AUTOSAR XML (schema 4-3-0)
standard types defined: uint8, uint8_DataConstr, boolean, uint16, sint16, sint32
package /ASP_DataTypes
  40 x impl type:
    accPedalPosition: category=VALUE, base-type=BaseTypes/uint8
    accPedalPositionQual: category=VALUE, base-type=BaseTypes/uint8, compu {0=Cx0_Unsafe, 1=Cx1_Safe, 2=Cx2_SNA; unit Enum}
    AEB_Input: category=STRUCTURE
      4 x element, all with category=TYPE_REFERENCE:
        collAvoidSnvtySetting: range raw 0..3, implementation-data-type=collAvoidSnvtySetting
        driverAEBOverrideQual: range raw 0..3, implementation-data-type=driverAEBOverrideQual
        collAvoidSnvtySettingQual: range raw 0..3, implementation-data-type=collAvoidSnvtySettingQual
        driverAEBOverride: implementation-data-type=driverAEBOverride
    brakePedalPressed: category=VALUE, base-type=BaseTypes/boolean, compu {0=Cx0_No, 1=Cx1_Yes; unit Enum}
    brakePedalPressedQual: category=VALUE, base-type=BaseTypes/uint8, compu {0=Cx0_Unsafe, 1=Cx1_Safe, 2=Cx2_SNA; unit Enum}
    brakeTorque: category=VALUE, base-type=BaseTypes/uint16
    collAvoidSnvtySetting: category=VALUE, base-type=BaseTypes/uint8, compu {0=Cx0_NotInUse, 1=Cx1_LoSnvty, 2=Cx2_NormSnvty, 3=Cx3_HiSnvty; unit Enum}
    collAvoidSnvtySettingQual: category=VALUE, base-type=BaseTypes/uint8, compu {0=Cx0_Unsafe, 1=Cx1_Safe, 2=Cx2_SNA; unit Enum}
    Common_Zenuity_Input: category=STRUCTURE
      7 x element, all with category=TYPE_REFERENCE:
        brakePedalPressed: implementation-data-type=brakePedalPressed
        steeringWhlAngle: range raw -16384..16383, implementation-data-type=steeringWhlAngle
        accPedalPositionQual: range raw 0..3, implementation-data-type=accPedalPositionQual
        steeringWhlAngleSpeed: range raw -65536..65535, implementation-data-type=steeringWhlAngleSpeed
        accPedalPosition: range raw 0..100, implementation-data-type=accPedalPosition
        driverBrakeTorque: range raw 0..20000, implementation-data-type=driverBrakeTorque
        brakePedalPressedQual: range raw 0..3, implementation-data-type=brakePedalPressedQual
    driverAEBOverride: category=VALUE, base-type=BaseTypes/boolean, compu {0=Cx0_No, 1=Cx1_Yes; unit Enum}
    driverAEBOverrideQual: category=VALUE, base-type=BaseTypes/uint8, compu {0=Cx0_Unsafe, 1=Cx1_Safe, 2=Cx2_SNA; unit Enum}
    driverBrakeTorque: category=VALUE, base-type=BaseTypes/uint16
    dynamicWheelRadiusFront: category=VALUE, base-type=BaseTypes/uint16
    dynamicWheelRadiusRear: category=VALUE, base-type=BaseTypes/uint16
    EgoMotion: category=STRUCTURE
      20 x element, all with category=TYPE_REFERENCE:
        dynamicWheelRadiusRear: range raw 0..4095, implementation-data-type=dynamicWheelRadiusRear
        lateralAccelerationQual: range raw 0..3, implementation-data-type=lateralAccelerationQual
        lateralAcceleration: range raw -2048..2047, implementation-data-type=lateralAcceleration
        longitudinalSpeedQual: range raw 0..3, implementation-data-type=longitudinalSpeedQual
        wheelSpeedFrontRight: range raw -8192..8191, implementation-data-type=wheelSpeedFrontRight
        dynamicWheelRadiusFront: range raw 0..4095, implementation-data-type=dynamicWheelRadiusFront
        wheelSpeedQual: range raw 0..3, implementation-data-type=wheelSpeedQual
        wheelSpeedFrontLeft: range raw -8192..8191, implementation-data-type=wheelSpeedFrontLeft
        longitudinalSpeed: range raw -8192..8191, implementation-data-type=longitudinalSpeed
        rearWheelAngleQual: range raw 0..3, implementation-data-type=rearWheelAngleQual
        wheelSpeedRearRight: range raw -8192..8191, implementation-data-type=wheelSpeedRearRight
        longitudinalAccelerationQual: range raw 0..3, implementation-data-type=longitudinalAccelerationQual
        frontWheelAngle: range raw -16384..16383, implementation-data-type=frontWheelAngle
        rearWheelAngle: range raw -16384..16383, implementation-data-type=rearWheelAngle
        wheelSpeedRearLeft: range raw -8192..8191, implementation-data-type=wheelSpeedRearLeft
        frontWheelAngleQual: range raw 0..3, implementation-data-type=frontWheelAngleQual
        longitudinalAcceleration: range raw -2048..2047, implementation-data-type=longitudinalAcceleration
        yawRate: implementation-data-type=yawRate
        yawRateQual: range raw 0..3, implementation-data-type=yawRateQual
        brakeTorque: range raw 0..16383, implementation-data-type=brakeTorque
    engineState: category=VALUE, base-type=BaseTypes/uint8, compu {0=Cx0_Stop, 1=Cx1_Start, 2=Cx2_Idle_Unstable (Idle Unstable), 3=Cx3_Idle_Stable (Idle Stable), 4=Cx4_Unlimited, 5=Cx5_Limited, 6=Cx6_SNA; unit Enum}
    frontWheelAngle: category=VALUE, base-type=sint16
    frontWheelAngleQual: category=VALUE, base-type=BaseTypes/uint8, compu {0=Cx0_Unavailable, 1=Cx1_Available, 2=Cx2_SNA; unit Enum}
    ignitionState: category=VALUE, base-type=BaseTypes/uint8, compu {0=Cx0_Lock, 1=Cx1_OFF, 2=Cx2_ACC, 3=Cx3_ON, 4=Cx4_Start, 5=Cx5_SNA; unit Enum}
    lateralAcceleration: category=VALUE, base-type=sint16
    lateralAccelerationQual: category=VALUE, base-type=BaseTypes/uint8, compu {0=Cx0_Unavailable, 1=Cx1_Available, 2=Cx2_SNA; unit Enum}
    longitudinalAcceleration: category=VALUE, base-type=sint16
    longitudinalAccelerationQual: category=VALUE, base-type=BaseTypes/uint8, compu {0=Cx0_Unavailable, 1=Cx1_Available, 2=Cx2_SNA; unit Enum}
    longitudinalSpeed: category=VALUE, base-type=sint16
    longitudinalSpeedQual: category=VALUE, base-type=BaseTypes/uint8, compu {0=Cx0_Unsafe, 1=Cx1_Safe, 2=Cx2_SNA; unit Enum}
    PositionInfoType: category=STRUCTURE, sw-calibration-access=READ-ONLY, type-emitter=RTE
      element countryCode: category=VALUE, base-type=BaseTypes/uint16, sw-calibration-access=READ-ONLY, invalid-value=1023  # Current country in ISO 3166-1 numerical
    rearWheelAngle: category=VALUE, base-type=sint16
    rearWheelAngleQual: category=VALUE, base-type=BaseTypes/uint8, compu {0=Cx0_Unavailable, 1=Cx1_Available, 2=Cx2_SNA; unit Enum}
    steeringWhlAngle: category=VALUE, base-type=sint16
    steeringWhlAngleSpeed: category=VALUE, base-type=sint32
    suspensionType: category=VALUE, base-type=BaseTypes/uint8
    turnIndicator: category=VALUE, base-type=BaseTypes/uint8
    VehicleData: category=STRUCTURE
      4 x element, all with category=TYPE_REFERENCE, range raw 0..7:
        suspensionType: implementation-data-type=suspensionType
        ignitionState: implementation-data-type=ignitionState
        turnIndicator: implementation-data-type=turnIndicator
        engineState: implementation-data-type=engineState
    wheelSpeedFrontLeft: category=VALUE, base-type=sint16
    wheelSpeedFrontRight: category=VALUE, base-type=sint16
    wheelSpeedQual: category=VALUE, base-type=BaseTypes/uint8, compu {0=Cx0_Unavailable, 1=Cx1_Available, 2=Cx2_SNA; unit Enum}
    wheelSpeedRearLeft: category=VALUE, base-type=sint16
    wheelSpeedRearRight: category=VALUE, base-type=sint16
    yawRate: category=VALUE, base-type=sint16
    yawRateQual: category=VALUE, base-type=BaseTypes/uint8, compu {0=Cx0_Unavailable, 1=Cx1_Available, 2=Cx2_SNA; unit Enum}
package /ASP_DataTypes/Units
  unit U_Enum: display-name=Enum, factor-si-to-unit=1, offset-si-to-unit=0
package /ASP_PortInterfaces
  sender receiver interface ASP_AEB_Input: invalidation-policy{data-element=AEB_Input, handle-invalid=DONT-INVALIDATE}
    data AEB_Input: type=AEB_Input
  sender receiver interface ASP_Common_Zenuity_Input: invalidation-policy{data-element=Common_Zenuity_Input, handle-invalid=DONT-INVALIDATE}
    data Common_Zenuity_Input: type=Common_Zenuity_Input
  sender receiver interface ASP_VehicleInput
    data EgoMotionElement: type=EgoMotion
    data PositionInfo: type=PositionInfoType
    data VehicleDataElement: type=VehicleData
    invalidation-policys:
      data-element=EgoMotionElement, handle-invalid=DONT-INVALIDATE
      data-element=VehicleDataElement, handle-invalid=DONT-INVALIDATE
      data-element=PositionInfo, handle-invalid=DONT-INVALIDATE
package /ComponentTypes/HkmcComponent/HkmcVehicleInputAdap
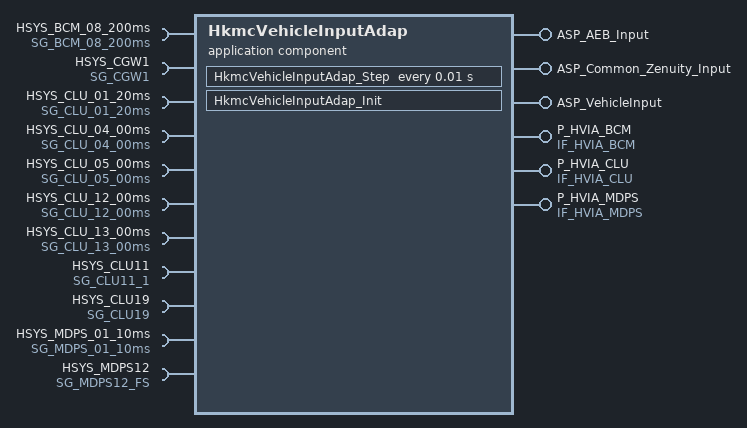
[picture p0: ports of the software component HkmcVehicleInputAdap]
  application sw component type HkmcVehicleInputAdap
    6 x provide port:
      ASP_AEB_Input: nonqueued-sender-com-spec{data-element=AEB_Input, init-value=fields=[collAvoidSnvtySetting:0, driverAEBOverrideQual:0, collAvoidSnvtySettingQual:0, driverAEBOverride:0]}, provided-interface=ASP_AEB_Input
      ASP_Common_Zenuity_Input: nonqueued-sender-com-spec{data-element=Common_Zenuity_Input, init-value=fields=[brakePedalPressed:0, steeringWhlAngle:0, accPedalPositionQual:0, steeringWhlAngleSpeed:0, accPedalPosition:0, driverBrakeTorque:0, brakePedalPressedQual:0]}, provided-interface=ASP_Common_Zenuity_Input
      ASP_VehicleInput: provided-interface=ASP_VehicleInput
        provided-com-specs:
          data-element=EgoMotionElement, init-value=fields=[dynamicWheelRadiusRear:0, lateralAccelerationQual:0, lateralAcceleration:0, longitudinalSpeedQual:0, wheelSpeedFrontRight:0, dynamicWheelRadiusFront:0, wheelSpeedQual:0, wheelSpeedFrontLeft:0, longitudinalSpeed:0, rearWheelAngleQual:0, wheelSpeedRearRight:0, longitudinalAccelerationQual:0, frontWheelAngle:0, rearWheelAngle:0, wheelSpeedRearLeft:0, frontWheelAngleQual:0, longitudinalAcceleration:0, yawRate:0, yawRateQual:0, brakeTorque:0]
          data-element=PositionInfo, init-value=fields=countryCode:0
          data-element=VehicleDataElement, init-value=fields=[suspensionType:0, ignitionState:0, turnIndicator:0, engineState:0]
      P_HVIA_BCM: nonqueued-sender-com-spec{data-element=HVIA_BCM, init-value=fields=HkmcVehInput_HBA_ControlMode:0}, provided-interface=IF_HVIA_BCM
      P_HVIA_CLU: nonqueued-sender-com-spec{data-element=DE_HVIA_CLU, init-value=fields=[HkmcVehicleInput_SpdUnitTyp:0, HkmcVehicleInput_Fca1stWrngSetReq:0, HkmcVehicleInput_AdasFCASetReq:0, HkmcVehicleInput_LkaModSetReq:0, HkmcVehInput_HBA_NValueSet:0, HkmcVehicleInput_AdasISLASetReq:0]}, provided-interface=IF_HVIA_CLU
      P_HVIA_MDPS: nonqueued-sender-com-spec{data-element=DE_HVIA_MDPS, init-value=fields=HkmcVehicleInput_LkaToiUnblSta:0}, provided-interface=IF_HVIA_MDPS
    11 x require port:
      HSYS_BCM_08_200ms: nonqueued-receiver-com-spec{data-element=SG_BCM_08_200ms, filter=data-filter-type=ALWAYS, init-value=fields=[BCM_AlvCnt8Val:0, BCM_Crc8Val:255, Lamp_HbaCtrlModTyp:0]}, required-interface=SG_BCM_08_200ms
      HSYS_CGW1: nonqueued-receiver-com-spec{data-element=SG_CGW1, filter=data-filter-type=ALWAYS, init-value=fields=[CF_Gway_AstDrSw:0, CF_Gway_DrvDrSw:0, CF_Gway_DrvSeatBeltSw:0, CF_Gway_HazardSw:0, CF_Gway_HBAControlMode:0, CF_Gway_HeadLampHigh:0, CF_Gway_HeadLampLow:0, CF_Gway_IGNSw:0, CF_Gway_InhibitRMT:0, CF_Gway_RainSnsState:0, CF_Gway_TSigLHSw:0, CF_Gway_TSigRHSw:0, CF_Gway_TurnSigLh:0, CF_Gway_TurnSigRh:0, CF_Gway_WiperAutoSw:0, CF_Gway_WiperHighSw:0, CF_Gway_WiperIntSw:0, CF_Gway_WiperIntT:0, CF_Gway_WiperLowSw:0]}, required-interface=SG_CGW1
      HSYS_CLU_01_20ms: nonqueued-receiver-com-spec{data-element=SG_CLU_01_20ms, filter=data-filter-type=ALWAYS, init-value=fields=[CLU_AlvCnt1Val:0, CLU_Crc1Val:65535, CLU_DisSpdVal:0, CLU_SpdUnitTyp:0, CLU_SWRCCrsMainSwSta:0, CLU_SWRCCrsSwSta:0, CLU_SWRCLFASwSta:0, CLU_SWRCSldMainSwSta:0]}, required-interface=SG_CLU_01_20ms
      HSYS_CLU_04_00ms: nonqueued-receiver-com-spec{data-element=SG_CLU_04_00ms, filter=data-filter-type=ALWAYS, init-value=fields=[USM_AdasISLAAutoSetReq:0, USM_AdasISLASetReq:0, USM_ISLAOffstSetReq:0]}, required-interface=SG_CLU_04_00ms
      HSYS_CLU_05_00ms: nonqueued-receiver-com-spec{data-element=SG_CLU_05_00ms, filter=data-filter-type=ALWAYS, init-value=fields=[USM_Fca1stWrngSetReq:0, USM_StaRst1Req:0]}, required-interface=SG_CLU_05_00ms
      HSYS_CLU_12_00ms: nonqueued-receiver-com-spec{data-element=SG_CLU_12_00ms, filter=data-filter-type=ALWAYS, init-value=fields=[CLU_AlvCnt12Val:0, CLU_Crc12Val:65535, USM_AdasFCASetReq:0, USM_AdasHDASetReq:0, USM_AdasISLWSetReq:0, USM_AdasLVDASetReq:0, USM_AdasNSCCCamSetReq:0, USM_AdasSCCDrvModSetReq:0, USM_AdasUSMResetReq:0, USM_AdasWrngTimingSetReq:0]}, required-interface=SG_CLU_12_00ms
      HSYS_CLU_13_00ms: nonqueued-receiver-com-spec{data-element=SG_CLU_13_00ms, filter=data-filter-type=ALWAYS, init-value=fields=[CLU_AdasDAWResetReq:0, CLU_AlvCnt13Val:0, CLU_Crc13Val:65535, USM_AdasDAWModNewSetReq:0, USM_AdasHbaSetReq:0, USM_AdasLkaModSetReq:0]}, required-interface=SG_CLU_13_00ms
      HSYS_CLU11: nonqueued-receiver-com-spec{data-element=SG_CLU11, filter=data-filter-type=ALWAYS, init-value=fields=[CF_Clu_AliveCnt1:0, CF_Clu_CruiseSwMain:0, CF_Clu_CruiseSwState:0, CF_Clu_SldMainSW:0, CF_Clu_SPEED_UNIT:0, CF_Clu_Vanz:0]}, required-interface=SG_CLU11_1
      HSYS_CLU19: nonqueued-receiver-com-spec{data-element=SG_CLU19, filter=data-filter-type=ALWAYS, init-value=fields=[CF_AVN_CluUSMReset:0, CF_AVN_DAWModeNValueSet_New:0, CF_AVN_FCANValueSet:0, CF_AVN_HBANValueSet:0, CF_AVN_HDA_NValueSet:0, CF_AVN_LkaModeNValueSet:0, CF_AVN_LVDANValueSet:0, CF_AVN_NSCCCamNValueSet:0, CF_AVN_WarningTimingNValueSet:0, CF_Clu_DawResetReq:0]}, required-interface=SG_CLU19
      HSYS_MDPS_01_10ms: nonqueued-receiver-com-spec{data-element=SG_MDPS_01_10ms, filter=data-filter-type=ALWAYS, init-value=fields=[MDPS_AlvCnt1Val:0, MDPS_Crc1Val:65535, MDPS_LkaPlgInSta:0, MDPS_LkaToiActvSta:0, MDPS_LkaToiFltSta:0, MDPS_LkaToiUnblSta:0, MDPS_PaModeSta:1, MDPS_StrTqSnsrVal:4096]}, required-interface=SG_MDPS_01_10ms
      HSYS_MDPS12: nonqueued-receiver-com-spec{data-element=SG_MDPS12_FS, filter=data-filter-type=ALWAYS, init-value=fields=[CF_Mdps12_CRC:255, CF_Mdps_FailStat:0, CF_Mdps_MsgCount2:0, CF_Mdps_ToiActive:0, CF_Mdps_ToiFlt:0, CF_Mdps_ToiUnavail:0, CR_Mdps_StrColTq:1024]}, required-interface=SG_MDPS12_FS
    behavior HkmcVehicleInputAdap_InternalBehavior
      init event HkmcVehicleInputAdap_InitEvent: start-on-event=HkmcVehicleInputAdap_Init
      timing event TMT_HkmcVehicleInputAdap_Step: start-on-event=HkmcVehicleInputAdap_Step, period=0.01
      runnable HkmcVehicleInputAdap_Init
        data-receive-point-by-arguments:
          11 x access:
            REC_HSYS_BCM_08_200ms_SG_BCM_08_200ms: accessed-variable=HSYS_BCM_08_200ms.SG_BCM_08_200ms
            REC_HSYS_CGW1_SG_CGW1: accessed-variable=HSYS_CGW1.SG_CGW1
            REC_HSYS_CLU_01_20ms_SG_CLU_01_20ms: accessed-variable=HSYS_CLU_01_20ms.SG_CLU_01_20ms
            REC_HSYS_CLU_04_00ms_SG_CLU_04_00ms: accessed-variable=HSYS_CLU_04_00ms.SG_CLU_04_00ms
            REC_HSYS_CLU_05_00ms_SG_CLU_05_00ms: accessed-variable=HSYS_CLU_05_00ms.SG_CLU_05_00ms
            REC_HSYS_CLU_12_00ms_SG_CLU_12_00ms: accessed-variable=HSYS_CLU_12_00ms.SG_CLU_12_00ms
            REC_HSYS_CLU_13_00ms_SG_CLU_13_00ms: accessed-variable=HSYS_CLU_13_00ms.SG_CLU_13_00ms
            REC_HSYS_CLU11_SG_CLU11: accessed-variable=HSYS_CLU11.SG_CLU11
            REC_HSYS_CLU19_SG_CLU19: accessed-variable=HSYS_CLU19.SG_CLU19
            REC_HSYS_MDPS_01_10ms_SG_MDPS_01_10ms: accessed-variable=HSYS_MDPS_01_10ms.SG_MDPS_01_10ms
            REC_HSYS_MDPS12_SG_MDPS12_FS: accessed-variable=HSYS_MDPS12.SG_MDPS12_FS
        data-send-points:
          8 x access:
            SEND_ASP_AEB_Input_AEB_Input: accessed-variable=ASP_AEB_Input.AEB_Input
            SEND_ASP_Common_Zenuity_Input_Common_Zenuity_Input: accessed-variable=ASP_Common_Zenuity_Input.Common_Zenuity_Input
            SEND_ASP_VehicleInput_EgoMotionElement: accessed-variable=ASP_VehicleInput.EgoMotionElement
            SEND_ASP_VehicleInput_PositionInfo: accessed-variable=ASP_VehicleInput.PositionInfo
            SEND_ASP_VehicleInput_VehicleDataElement: accessed-variable=ASP_VehicleInput.VehicleDataElement
            SEND_P_HVIA_BCM_HVIA_BCM: accessed-variable=P_HVIA_BCM.HVIA_BCM
            SEND_P_HVIA_CLU_DE_HVIA_CLU: accessed-variable=P_HVIA_CLU.DE_HVIA_CLU
            SEND_P_HVIA_MDPS_DE_HVIA_MDPS: accessed-variable=P_HVIA_MDPS.DE_HVIA_MDPS
      runnable HkmcVehicleInputAdap_Step
        data-receive-point-by-arguments:
          11 x access:
            REC_HSYS_BCM_08_200ms_SG_BCM_08_200ms: accessed-variable=HSYS_BCM_08_200ms.SG_BCM_08_200ms
            REC_HSYS_CGW1_SG_CGW1: accessed-variable=HSYS_CGW1.SG_CGW1
            REC_HSYS_CLU_01_20ms_SG_CLU_01_20ms: accessed-variable=HSYS_CLU_01_20ms.SG_CLU_01_20ms
            REC_HSYS_CLU_04_00ms_SG_CLU_04_00ms: accessed-variable=HSYS_CLU_04_00ms.SG_CLU_04_00ms
            REC_HSYS_CLU_05_00ms_SG_CLU_05_00ms: accessed-variable=HSYS_CLU_05_00ms.SG_CLU_05_00ms
            REC_HSYS_CLU_12_00ms_SG_CLU_12_00ms: accessed-variable=HSYS_CLU_12_00ms.SG_CLU_12_00ms
            REC_HSYS_CLU_13_00ms_SG_CLU_13_00ms: accessed-variable=HSYS_CLU_13_00ms.SG_CLU_13_00ms
            REC_HSYS_CLU11_SG_CLU11: accessed-variable=HSYS_CLU11.SG_CLU11
            REC_HSYS_CLU19_SG_CLU19: accessed-variable=HSYS_CLU19.SG_CLU19
            REC_HSYS_MDPS_01_10ms_SG_MDPS_01_10ms: accessed-variable=HSYS_MDPS_01_10ms.SG_MDPS_01_10ms
            REC_HSYS_MDPS12_SG_MDPS12_FS: accessed-variable=HSYS_MDPS12.SG_MDPS12_FS
        data-send-points:
          8 x access:
            SEND_ASP_AEB_Input_AEB_Input: accessed-variable=ASP_AEB_Input.AEB_Input
            SEND_ASP_Common_Zenuity_Input_Common_Zenuity_Input: accessed-variable=ASP_Common_Zenuity_Input.Common_Zenuity_Input
            SEND_ASP_VehicleInput_EgoMotionElement: accessed-variable=ASP_VehicleInput.EgoMotionElement
            SEND_ASP_VehicleInput_PositionInfo: accessed-variable=ASP_VehicleInput.PositionInfo
            SEND_ASP_VehicleInput_VehicleDataElement: accessed-variable=ASP_VehicleInput.VehicleDataElement
            SEND_P_HVIA_BCM_HVIA_BCM: accessed-variable=P_HVIA_BCM.HVIA_BCM
            SEND_P_HVIA_CLU_DE_HVIA_CLU: accessed-variable=P_HVIA_CLU.DE_HVIA_CLU
            SEND_P_HVIA_MDPS_DE_HVIA_MDPS: accessed-variable=P_HVIA_MDPS.DE_HVIA_MDPS
  swc implementation HkmcVehicleInputAdap_Implementation: behavior=HkmcVehicleInputAdap_InternalBehavior
    code-descriptors:
      code Default: artifact-descriptors=autosar-engineering-object={short-label=Default, category=SWSRC}
package /ComponentTypes/HkmcComponent/HkmcVehicleInputAdap/DataTypes
  impl type HVIA_BCM_T: category=STRUCTURE, sw-calibration-access=READ-ONLY, type-emitter=RTE
    element HkmcVehInput_HBA_ControlMode: compu {0=Cx0_ContM_HighControlMode_BCM, 1=Cx1_ContM_HighControlMode_HBA, 2=Cx2_ContM_Not_Used, 3=Cx3_ContM_Error_Indicator}, implementation-data-type=uint8
  impl type HVIA_CLU_T: category=STRUCTURE, sw-calibration-access=READ-ONLY, type-emitter=RTE
    6 x element, all with category=TYPE_REFERENCE, implementation-data-type=uint8:
      HkmcVehicleInput_SpdUnitTyp: compu {0=Cx0_SpdUT_kmperh, 1=Cx1_SpdUT_MPH, 2=Cx2_SpdUT_Not_used, 3=Cx3_SpdUT_Error_Indicator}
      HkmcVehicleInput_Fca1stWrngSetReq: compu {0=Cx0_Fca1stWSR_Default, 1=Cx1_Fca1stWSR_Late, 2=Cx2_Fca1stWSR_Normal, 3=Cx3_Fca1stWSR_Early, 4=Cx4_Fca1stWSR_Reserved, 5=Cx5_Fca1stWSR_Reserved, 6=Cx6_Fca1stWSR_Reserved, 7=Cx7_Fca1stWSR_Invalid, 8=Cx8_Fca1stWSR_Reserved, 9=Cx9_Fca1stWSR_Reserved, 16=Cx10_Fca1stWSR_Reserved, 17=Cx11_Fca1stWSR_Reserved}
      HkmcVehicleInput_AdasFCASetReq: compu {0=Cx0_AdasFCASR_Default, 1=Cx1_AdasFCASR_Off, 2=Cx2_AdasFCASR_Warning, 3=Cx3_AdasFCASR_Assist, 4=Cx4_AdasFCASR_Reserved, 5=Cx5_AdasFCASR_Reserved, 6=Cx6_AdasFCASR_Reserved, 7=Cx7_AdasFCASR_Invalid}
      HkmcVehicleInput_LkaModSetReq: compu {0=Cx0_LkaModSR_Default, 1=Cx1_LkaModSR_LDW_mode, 2=Cx2_LkaModSR_LKA_mode, 3=Cx3_LkaModSR_Reserved, 4=Cx4_LkaModSR_LDW_ON, 5=Cx5_LkaModSR_LDW_OFF, 6=Cx6_LkaModSR_LDW_LKA_OFF, 7=Cx7_LkaModSR_Invalid}
      HkmcVehInput_HBA_NValueSet: compu {0=Cx0_NVS_Default, 1=Cx1_NVS_HBA_Function_Off, 2=Cx2_NVS_HBA_Funtion_On, 3=Cx3_NVS_Invalid}
      HkmcVehicleInput_AdasISLASetReq: compu {0=Cx0_AdasSetReq_Default, 1=Cx1_AdasSetReq_Off, 2=Cx2_AdasSetReq_ISLW, 3=Cx3_AdasSetReq_ISLA, 4=Cx4_AdasSetReq_Reserved, 5=Cx5_AdasSetReq_Reserved, 6=Cx6_AdasSetReq_Reserved, 7=Cx7_AdasSetReq_Invalid}
  impl type HVIA_MDPS_T: category=STRUCTURE, sw-calibration-access=READ-ONLY, type-emitter=RTE
    element HkmcVehicleInput_LkaToiUnblSta: compu {0=Cx0_LkaTUS_Available, 1=Cx1_LkaTUS_Unavailable, 2=Cx2_LkaTUS_Not_Used, 3=Cx3_LkaTUS_Error_Indicator}, implementation-data-type=uint8
package /ComponentTypes/HkmcComponent/HkmcVehicleInputAdap/PortInterfaces
  sender receiver interface IF_HVIA_BCM: invalidation-policy{data-element=HVIA_BCM, handle-invalid=DONT-INVALIDATE}
    data HVIA_BCM: type=HVIA_BCM_T
  sender receiver interface IF_HVIA_CLU: invalidation-policy{data-element=DE_HVIA_CLU, handle-invalid=DONT-INVALIDATE}
    data DE_HVIA_CLU: type=HVIA_CLU_T
  sender receiver interface IF_HVIA_MDPS: invalidation-policy{data-element=DE_HVIA_MDPS, handle-invalid=DONT-INVALIDATE}
    data DE_HVIA_MDPS: type=HVIA_MDPS_T
package /DataTypes
  93 x impl type:
    BCM_AlvCnt8Val: category=VALUE, base-type=DataType/uint8
    BCM_Crc8Val: category=VALUE, base-type=DataType/uint8
    CF_AVN_CluUSMReset: category=VALUE, base-type=DataType/boolean, compu {0=Cx0_CluUSMR_Default, 1=Cx1_CluUSMR_Reset}
    CF_AVN_DAWModeNValueSet_New: category=VALUE, base-type=DataType/uint8, compu {0=Cx0_DAWMNVSN_Default, 1=Cx1_DAWMNVSN_Off, 2=Cx2_DAWMNVSN_On, 3=Cx3_DAWMNVSN_Invalid}
    CF_AVN_FCANValueSet: category=VALUE, base-type=DataType/uint8, compu {0=Cx0_FCANVS_Default, 1=Cx1_FCANVS_Off, 2=Cx2_FCANVS_Warning, 3=Cx3_FCANVS_Assist, 4=Cx4_FCANVS_Reserved, 5=Cx5_FCANVS_Reserved, 6=Cx6_FCANVS_Reserved, 7=Cx7_FCANVS_Invalid}
    CF_AVN_HBANValueSet: category=VALUE, base-type=DataType/uint8, compu {0=Cx0_HBANVS_Default, 1=Cx1_HBANVS_HBAOff, 2=Cx2_HBANVS_HBAOn, 3=Cx3_HBANVS_Invalid}
    CF_AVN_HDA_NValueSet: category=VALUE, base-type=DataType/uint8, compu {0=Cx0_HDANVS_Default, 1=Cx1_HDANVS_Function_Off (Function Off), 2=Cx2_HDANVS_Function_On (Function On), 3=Cx3_HDANVS_Invalid (Invalid(Fail))}
    CF_AVN_LkaModeNValueSet: category=VALUE, base-type=DataType/uint8, compu {0=Cx0_LkaMNVS_Default, 1=Cx1_LkaMNVS_LDW_mode, 2=Cx2_LkaMNVS_LKA, 3=Cx3_LkaMNVS_Reserved, 4=Cx4_LkaMNVS_LDW_only_ON, 5=Cx5_LkaMNVS_LDW_only_OFF, 6=Cx6_LkaMNVS_LDW_LKA_OFF, 7=Cx7_LkaMNVS_Invalid}
    CF_AVN_LVDANValueSet: category=VALUE, base-type=DataType/uint8, compu {0=Cx0_LVDANLVS_Default, 1=Cx1_LVDANLVS_Off, 2=Cx2_LVDANLVS_On, 3=Cx3_LVDANLVS_Invalid}
    CF_AVN_NSCCCamNValueSet: category=VALUE, base-type=DataType/uint8, compu {0=Cx0_NSCCCNVS_Default, 1=Cx1_NSCCCNVS_Disable, 2=Cx2_NSCCCNVS_Enable, 3=Cx3_NSCCCNVS_Invalid}
    CF_AVN_WarningTimingNValueSet: category=VALUE, base-type=DataType/uint8, compu {0=Cx0_WarnTNVS_Default, 1=Cx1_WarnTNVS_Late, 2=Cx2_WarnTNVS_Normal, 3=Cx3_WarnTNVS_Reserved, 4=Cx4_WarnTNVS_Reserved, 5=Cx5_WarnTNVS_Reserved, 6=Cx6_WarnTNVS_Reserved, 7=Cx7_WarnTNVS_Invalid}
    CF_Clu_AliveCnt1: category=VALUE, base-type=DataType/uint8
    CF_Clu_CruiseSwMain: category=VALUE, base-type=DataType/boolean, compu {0=Cx0_CruiseSM_Off, 1=Cx1_CruiseSM_On}
    CF_Clu_CruiseSwState: category=VALUE, base-type=DataType/uint8, compu {0=Cx0_CruiseSS_IdlePosition, 1=Cx1_CruiseSS_Plus, 2=Cx2_CruiseSS_Minus, 3=Cx3_CruiseSS_Time_Gap, 4=Cx4_CruiseSS_Cancel_Pause, 5=Cx5_CruiseSS_Reserved, 6=Cx6_CruiseSS_Reserved, 7=Cx7_CruiseSS_Reserved}
    CF_Clu_DawResetReq: category=VALUE, base-type=DataType/boolean, compu {0=Cx0_DawRR_Default, 1=Cx1_DawRR_ResetReq}
    CF_Clu_SldMainSW: category=VALUE, base-type=DataType/boolean, compu {0=Cx0_SldMS_Off, 1=Cx1_SldSMS_On}
    CF_Clu_SPEED_UNIT: category=VALUE, base-type=DataType/boolean, compu {0=Cx0_SpeedU_kmperh, 1=Cx1_SpeedU_MPH}
    CF_Clu_Vanz: category=VALUE, base-type=DataType/uint16
    CF_Gway_AstDrSw: category=VALUE, base-type=DataType/boolean, compu {0=Cx0_AstDS_Close, 1=Cx1_AstDS_Open}
    CF_Gway_DrvDrSw: category=VALUE, base-type=DataType/uint8, compu {0=Cx0_DrvDS_Close, 1=Cx1_DrvDS_Open, 3=Cx3_DrvDS_BCANSignalTimeOut}
    CF_Gway_DrvSeatBeltSw: category=VALUE, base-type=DataType/uint8, compu {0=Cx0_DrvSBS_Unbelted, 1=Cx1_DrvSBS_Belted, 3=Cx3_DrvSBS_BCANSignalTimeOut}
    CF_Gway_HazardSw: category=VALUE, base-type=DataType/uint8, compu {0=Cx0_HazS_Off, 1=Cx1_HazS_On, 3=Cx3_HazS_BCANSignalTimeOut}
    CF_Gway_HBAControlMode: category=VALUE, base-type=DataType/boolean, compu {0=Cx0_HCM_HighControlModebyBCM, 1=Cx1_HCM_HighControlModebyHBA}
    CF_Gway_HeadLampHigh: category=VALUE, base-type=DataType/boolean, compu {0=Cx0_HeadLH_Off, 1=Cx1_HeadLH_On}
    CF_Gway_HeadLampLow: category=VALUE, base-type=DataType/boolean, compu {0=Cx0_HeadLL_Off, 1=Cx1_HeadLL_On}
    CF_Gway_IGNSw: category=VALUE, base-type=DataType/uint8, compu {0=Cx0_IGNS_KeyOff, 1=Cx1_IGNS_KeyIn, 2=Cx2_IGNS_ACC, 3=Cx3_IGNS_IGN, 4=Cx4_IGNS_Start, 5=Cx5_IGNS_Reserved, 6=Cx6_IGNS_Reserved, 7=Cx7_IGNS_BCANSignalTimeOut}
    CF_Gway_InhibitRMT: category=VALUE, base-type=DataType/uint8, compu {0=Cx0_IRMT_GearRSwitchOff, 1=Cx1_IRMT_GearRSwitchOn, 3=Cx3_IRMT_BCANSignalTimeOut}
    CF_Gway_RainSnsState: category=VALUE, base-type=DataType/uint8, compu {0=Cx0_RainSS_OFF, 1=Cx1_RainSS_Rain_Detected, 2=Cx2_RainSS_Low, 3=Cx3_RainSS_High, 4=Cx4_RainSS_Fault1, 5=Cx5_RainSS_Fault2, 6=Cx6_RainSS_Fault3, 7=Cx7_RainSS_Reserved}
    CF_Gway_TSigLHSw: category=VALUE, base-type=DataType/boolean, compu {0=Cx0_TSLS_Off, 1=Cx1_TSLS_On}
    CF_Gway_TSigRHSw: category=VALUE, base-type=DataType/boolean, compu {0=Cx0_TSRS_Off, 1=Cx1_TSRS_On}
    CF_Gway_TurnSigLh: category=VALUE, base-type=DataType/uint8, compu {0=Cx0_TurnSL_Off, 1=Cx1_TurnSL_On, 3=Cx3_TurnSL_BCANSignalTimeOut}
    CF_Gway_TurnSigRh: category=VALUE, base-type=DataType/uint8, compu {0=Cx0_TurnSR_Off, 1=Cx1_TurnSR_On, 3=Cx3_TurnSR_BCANSignalTimeOut}
    CF_Gway_WiperAutoSw: category=VALUE, base-type=DataType/boolean, compu {0=Cx0_WiperAS_Off, 1=Cx1_WiperAS_On}
    CF_Gway_WiperHighSw: category=VALUE, base-type=DataType/boolean, compu {0=Cx0_WiperHS_Off, 1=Cx1_WiperHS_On}
    CF_Gway_WiperIntSw: category=VALUE, base-type=DataType/boolean, compu {0=Cx0_WiperIS_Off, 1=Cx1_WiperIS_On}
    CF_Gway_WiperIntT: category=VALUE, base-type=DataType/uint8, compu {0=Cx0_WiperIT_Step1, 1=Cx1_WiperIT_Step2, 2=Cx2_WiperIT_Step3, 3=Cx3_WiperIT_Step4, 4=Cx4_WiperIT_Step5}
    CF_Gway_WiperLowSw: category=VALUE, base-type=DataType/boolean, compu {0=Cx0_WiperLS_Off, 1=Cx1_WiperLS_On}
    CF_Mdps_FailStat: category=VALUE, base-type=DataType/boolean, compu {0=Cx0_MdpsFS_NotFailState, 1=Cx1_MdpsFS_FailState}
    CF_Mdps_MsgCount2: category=VALUE, base-type=DataType/uint8
    CF_Mdps_ToiActive: category=VALUE, base-type=DataType/boolean, compu {0=Cx0_TA_Deactivated, 1=Cx1_TA_Activated}
    CF_Mdps_ToiFlt: category=VALUE, base-type=DataType/boolean, compu {0=Cx0_TF_NoFault, 1=Cx1_TF_Faulty}
    CF_Mdps_ToiUnavail: category=VALUE, base-type=DataType/boolean, compu {0=Cx0_TU_Available, 1=Cx1_TU_Unavailable}
    CF_Mdps12_CRC: category=VALUE, base-type=DataType/uint8
    CLU_AdasDAWResetReq: category=VALUE, base-type=DataType/uint8, compu {0=Cx0_AdasDAWRR_Default, 1=Cx1_AdasDAWRR_ResetReq, 2=Cx2_AdasDAWRR_Reserved, 3=Cx3_AdasDAWRR_Invalid}
    CLU_AlvCnt12Val: category=VALUE, base-type=DataType/uint8
    CLU_AlvCnt13Val: category=VALUE, base-type=DataType/uint8
    CLU_AlvCnt1Val: category=VALUE, base-type=DataType/uint8
    CLU_Crc12Val: category=VALUE, base-type=DataType/uint16
    CLU_Crc13Val: category=VALUE, base-type=DataType/uint16
    CLU_Crc1Val: category=VALUE, base-type=DataType/uint16
    CLU_DisSpdVal: category=VALUE, base-type=DataType/uint16
    CLU_SpdUnitTyp: category=VALUE, base-type=DataType/uint8, compu {0=Cx0_SpdUT_kmperh, 1=Cx1_SpdUT_MPH, 2=Cx2_SpdUT_Not_used, 3=Cx3_SpdUT_Error_Indicator}
    CLU_SWRCCrsMainSwSta: category=VALUE, base-type=DataType/uint8, compu {0=Cx0_SWRCCMSS_off, 1=Cx1_SWRCCMSS_Key_On, 2=Cx2_SWRCCMSS_Reserved, 3=Cx3_SWRCCMSS_Invalid}
    CLU_SWRCCrsSwSta: category=VALUE, base-type=DataType/uint8, compu {0=Cx0_SWRCCSS_Idle_Position, 1=Cx1_SWRCCSS_Plus, 2=Cx2_SWRCCSS_Minus, 3=Cx3_SWRCCSS_Headway, 4=Cx4_SWRCCSS_Cancel_Pause, 5=Cx5_SWRCCSS_Reserved, 6=Cx6_SWRCCSS_Reserved, 7=Cx7_SWRCCSS_Reserved}
    CLU_SWRCLFASwSta: category=VALUE, base-type=DataType/uint8, compu {0=Cx0_SWRCLFASS_Off, 1=Cx1_SWRCLFASS_Key_On, 2=Cx2_SWRCLFASS_Reserved, 3=Cx3_SWRCLFASS_Invalid}
    CLU_SWRCSldMainSwSta: category=VALUE, base-type=DataType/uint8, compu {0=Cx0_SWRCSMSS_Off, 1=Cx1_SWRCSMSS_Key_On, 2=Cx2_SWRCSMSS_Reserved, 3=Cx3_SWRCSMSS_Invalid}
    CR_Mdps_StrColTq: category=VALUE, base-type=DataType/uint16
    HSYS_BCM_08_200ms_T: category=STRUCTURE
      element BCM_AlvCnt8Val: range raw 0..15, implementation-data-type=BCM_AlvCnt8Val
      element BCM_Crc8Val: range raw 0..255, implementation-data-type=BCM_Crc8Val
      element Lamp_HbaCtrlModTyp: range raw 0..3, implementation-data-type=Lamp_HbaCtrlModTyp
    HSYS_CGW1_T: category=STRUCTURE
      19 x element, all with category=TYPE_REFERENCE:
        CF_Gway_AstDrSw: implementation-data-type=CF_Gway_AstDrSw
        CF_Gway_DrvDrSw: range raw 0..3, implementation-data-type=CF_Gway_DrvDrSw
        CF_Gway_DrvSeatBeltSw: range raw 0..3, implementation-data-type=CF_Gway_DrvSeatBeltSw
        CF_Gway_HazardSw: range raw 0..3, implementation-data-type=CF_Gway_HazardSw
        CF_Gway_HBAControlMode: implementation-data-type=CF_Gway_HBAControlMode
        CF_Gway_HeadLampHigh: implementation-data-type=CF_Gway_HeadLampHigh
        CF_Gway_HeadLampLow: implementation-data-type=CF_Gway_HeadLampLow
        CF_Gway_IGNSw: range raw 0..7, implementation-data-type=CF_Gway_IGNSw
        CF_Gway_InhibitRMT: range raw 0..3, implementation-data-type=CF_Gway_InhibitRMT
        CF_Gway_RainSnsState: range raw 0..7, implementation-data-type=CF_Gway_RainSnsState
        CF_Gway_TSigLHSw: implementation-data-type=CF_Gway_TSigLHSw
        CF_Gway_TSigRHSw: implementation-data-type=CF_Gway_TSigRHSw
        CF_Gway_TurnSigLh: range raw 0..3, implementation-data-type=CF_Gway_TurnSigLh
        CF_Gway_TurnSigRh: range raw 0..3, implementation-data-type=CF_Gway_TurnSigRh
        CF_Gway_WiperAutoSw: implementation-data-type=CF_Gway_WiperAutoSw
        CF_Gway_WiperHighSw: implementation-data-type=CF_Gway_WiperHighSw
        CF_Gway_WiperIntSw: implementation-data-type=CF_Gway_WiperIntSw
        CF_Gway_WiperIntT: range raw 0..7, implementation-data-type=CF_Gway_WiperIntT
        CF_Gway_WiperLowSw: implementation-data-type=CF_Gway_WiperLowSw
    HSYS_CLU_01_20ms_T: category=STRUCTURE
      8 x element, all with category=TYPE_REFERENCE:
        CLU_AlvCnt1Val: range raw 0..255, implementation-data-type=CLU_AlvCnt1Val
        CLU_Crc1Val: range raw 0..65535, implementation-data-type=CLU_Crc1Val
        CLU_DisSpdVal: range raw 0..1023, implementation-data-type=CLU_DisSpdVal
        CLU_SpdUnitTyp: range raw 0..3, implementation-data-type=CLU_SpdUnitTyp
        CLU_SWRCCrsMainSwSta: range raw 0..3, implementation-data-type=CLU_SWRCCrsMainSwSta
        CLU_SWRCCrsSwSta: range raw 0..7, implementation-data-type=CLU_SWRCCrsSwSta
        CLU_SWRCLFASwSta: range raw 0..3, implementation-data-type=CLU_SWRCLFASwSta
        CLU_SWRCSldMainSwSta: range raw 0..3, implementation-data-type=CLU_SWRCSldMainSwSta
    HSYS_CLU_04_00ms_T: category=STRUCTURE
      element USM_AdasISLAAutoSetReq: range raw 0..3, implementation-data-type=USM_AdasISLAAutoSetReq
      element USM_AdasISLASetReq: range raw 0..7, implementation-data-type=USM_AdasISLASetReq
      element USM_ISLAOffstSetReq: range raw 0..7, implementation-data-type=USM_ISLAOffstSetReq
    HSYS_CLU_05_00ms_T: category=STRUCTURE
      element USM_Fca1stWrngSetReq: range raw 0..7, implementation-data-type=USM_Fca1stWrngSetReq
      element USM_StaRst1Req: range raw 0..3, implementation-data-type=USM_StaRst1Req
    HSYS_CLU_12_00ms_T: category=STRUCTURE
      10 x element, all with category=TYPE_REFERENCE:
        CLU_AlvCnt12Val: range raw 0..255, implementation-data-type=CLU_AlvCnt12Val
        CLU_Crc12Val: range raw 0..65535, implementation-data-type=CLU_Crc12Val
        USM_AdasFCASetReq: range raw 0..7, implementation-data-type=USM_AdasFCASetReq
        USM_AdasHDASetReq: range raw 0..3, implementation-data-type=USM_AdasHDASetReq
        USM_AdasISLWSetReq: range raw 0..3, implementation-data-type=USM_AdasISLWSetReq
        USM_AdasLVDASetReq: range raw 0..3, implementation-data-type=USM_AdasLVDASetReq
        USM_AdasNSCCCamSetReq: range raw 0..3, implementation-data-type=USM_AdasNSCCCamSetReq
        USM_AdasSCCDrvModSetReq: range raw 0..7, implementation-data-type=USM_AdasSCCDrvModSetReq
        USM_AdasUSMResetReq: range raw 0..3, implementation-data-type=USM_AdasUSMResetReq
        USM_AdasWrngTimingSetReq: range raw 0..7, implementation-data-type=USM_AdasWrngTimingSetReq
    HSYS_CLU_13_00ms_T: category=STRUCTURE
      6 x element, all with category=TYPE_REFERENCE:
        CLU_AdasDAWResetReq: range raw 0..3, implementation-data-type=CLU_AdasDAWResetReq
        CLU_AlvCnt13Val: range raw 0..255, implementation-data-type=CLU_AlvCnt13Val
        CLU_Crc13Val: range raw 0..65535, implementation-data-type=CLU_Crc13Val
        USM_AdasDAWModNewSetReq: range raw 0..3, implementation-data-type=USM_AdasDAWModNewSetReq
        USM_AdasHbaSetReq: range raw 0..3, implementation-data-type=USM_AdasHbaSetReq
        USM_AdasLkaModSetReq: range raw 0..7, implementation-data-type=USM_AdasLkaModSetReq
    HSYS_CLU11_T: category=STRUCTURE
      6 x element, all with category=TYPE_REFERENCE:
        CF_Clu_AliveCnt1: range raw 0..15, implementation-data-type=CF_Clu_AliveCnt1
        CF_Clu_CruiseSwMain: implementation-data-type=CF_Clu_CruiseSwMain
        CF_Clu_CruiseSwState: range raw 0..7, implementation-data-type=CF_Clu_CruiseSwState
        CF_Clu_SldMainSW: implementation-data-type=CF_Clu_SldMainSW
        CF_Clu_SPEED_UNIT: implementation-data-type=CF_Clu_SPEED_UNIT
        CF_Clu_Vanz: range raw 0..511, implementation-data-type=CF_Clu_Vanz
    HSYS_CLU19_T: category=STRUCTURE
      10 x element, all with category=TYPE_REFERENCE:
        CF_AVN_CluUSMReset: implementation-data-type=CF_AVN_CluUSMReset
        CF_AVN_DAWModeNValueSet_New: range raw 0..3, implementation-data-type=CF_AVN_DAWModeNValueSet_New
        CF_AVN_FCANValueSet: range raw 0..7, implementation-data-type=CF_AVN_FCANValueSet
        CF_AVN_HBANValueSet: range raw 0..3, implementation-data-type=CF_AVN_HBANValueSet
        CF_AVN_HDA_NValueSet: range raw 0..3, implementation-data-type=CF_AVN_HDA_NValueSet
        CF_AVN_LkaModeNValueSet: range raw 0..7, implementation-data-type=CF_AVN_LkaModeNValueSet
        CF_AVN_LVDANValueSet: range raw 0..3, implementation-data-type=CF_AVN_LVDANValueSet
        CF_AVN_NSCCCamNValueSet: range raw 0..3, implementation-data-type=CF_AVN_NSCCCamNValueSet
        CF_AVN_WarningTimingNValueSet: range raw 0..7, implementation-data-type=CF_AVN_WarningTimingNValueSet
        CF_Clu_DawResetReq: implementation-data-type=CF_Clu_DawResetReq
    HSYS_MDPS_01_10ms_T: category=STRUCTURE
      8 x element, all with category=TYPE_REFERENCE:
        MDPS_AlvCnt1Val: range raw 0..255, implementation-data-type=MDPS_AlvCnt1Val
        MDPS_Crc1Val: range raw 0..65535, implementation-data-type=MDPS_Crc1Val
        MDPS_LkaPlgInSta: range raw 0..3, implementation-data-type=MDPS_LkaPlgInSta
        MDPS_LkaToiActvSta: range raw 0..3, implementation-data-type=MDPS_LkaToiActvSta
        MDPS_LkaToiFltSta: range raw 0..3, implementation-data-type=MDPS_LkaToiFltSta
        MDPS_LkaToiUnblSta: range raw 0..3, implementation-data-type=MDPS_LkaToiUnblSta
        MDPS_PaModeSta: range raw 0..15, implementation-data-type=MDPS_PaModeSta
        MDPS_StrTqSnsrVal: range raw 0..8191, implementation-data-type=MDPS_StrTqSnsrVal
    HSYS_MDPS12_T: category=STRUCTURE
      7 x element, all with category=TYPE_REFERENCE:
        CF_Mdps12_CRC: range raw 0..255, implementation-data-type=CF_Mdps12_CRC
        CF_Mdps_FailStat: implementation-data-type=CF_Mdps_FailStat
        CF_Mdps_MsgCount2: range raw 0..255, implementation-data-type=CF_Mdps_MsgCount2
        CF_Mdps_ToiActive: implementation-data-type=CF_Mdps_ToiActive
        CF_Mdps_ToiFlt: implementation-data-type=CF_Mdps_ToiFlt
        CF_Mdps_ToiUnavail: implementation-data-type=CF_Mdps_ToiUnavail
        CR_Mdps_StrColTq: range raw 0..2047, implementation-data-type=CR_Mdps_StrColTq
    Lamp_HbaCtrlModTyp: category=VALUE, base-type=DataType/uint8, compu {0=Cx0_HbaCMT_HighControlMode_BCM, 1=Cx1_HbaCMT_HighControlMode_HBA, 2=Cx2_HbaCMT_Not_Used, 3=Cx3_HbaCMT_Error_Indicator}
    MDPS_AlvCnt1Val: category=VALUE, base-type=DataType/uint8
    MDPS_Crc1Val: category=VALUE, base-type=DataType/uint16
    MDPS_LkaPlgInSta: category=VALUE, base-type=DataType/uint8, compu {0=Cx0_LkaPIS_MDPS_Not_Plugged, 1=Cx1_LkaPIS_MDPS_Plugged_In, 2=Cx2_LkaPIS_Not_Used, 3=Cx3_LkaPIS_Error_Indicator}
    MDPS_LkaToiActvSta: category=VALUE, base-type=DataType/uint8, compu {0=Cx0_LkaTAS_Deactivated, 1=Cx1_LkaTAS_Activated, 2=Cx2_LkaTAS_Not_Used, 3=Cx3_LkaTAS_Error_Indicator}
    MDPS_LkaToiFltSta: category=VALUE, base-type=DataType/uint8, compu {0=Cx0_LkaTFS_No_Fault, 1=Cx1_LkaTFS_Faulty, 2=Cx2_LkaTFS_Not_used, 3=Cx3_LkaTFS_Error_Indicator}
    MDPS_LkaToiUnblSta: category=VALUE, base-type=DataType/uint8, compu {0=Cx0_LkaTUS_Available, 1=Cx1_LkaTUS_Unavailable, 2=Cx2_LkaTUS_Not_used, 3=Cx3_LkaTUS_Error_Indicator}
    MDPS_PaModeSta:
      category=VALUE
      base-type=DataType/uint8
      compu {0=Cx0_PMS_Reserved, 1=Cx1_PMS_Steering_still_in_initialization_phas, 2=Cx2_PMS_Steering_ready_waits_for_PA_command, 3=Cx3_PMS_Steering_set_in_standby_PA, 4=Cx4_PMS_Steering_requested_to_go_to_first_activation_step, 5=Cx5_PMS_Steering_requested_to_go_to_final_activation_step, 6=Cx6_PMS_Steering_went_to_error_internally, 7=Cx7_PMS_Steering_aborted_the_automatic_function, 15=CxE_PMS_Not_Used, 16=CxF_PMS_Error_Indicator}
    MDPS_StrTqSnsrVal: category=VALUE, base-type=DataType/uint16
    USM_AdasDAWModNewSetReq: category=VALUE, base-type=DataType/uint8, compu {0=Cx0_AdasDAWMNSR_Default, 1=Cx1_AdasDAWMNSR_Off, 2=Cx2_AdasDAWMNSR_On, 3=Cx3_AdasDAWMNSR_Invalid}
    USM_AdasFCASetReq: category=VALUE, base-type=DataType/uint8, compu {0=Cx0_AdasFCASR_Default, 1=Cx1_AdasFCASR_Off, 2=Cx2_AdasFCASR_Warning, 3=Cx3_AdasFCASR_Assist, 4=Cx4_AdasFCASR_Reserved, 5=Cx5_AdasFCASR_Reserved, 6=Cx6_AdasFCASR_Reserved, 7=Cx7_AdasFCASR_Invalid}
    USM_AdasHbaSetReq: category=VALUE, base-type=DataType/uint8, compu {0=Cx0_AdasHbaSR_Default, 1=Cx1_AdasHbaSR_Off, 2=Cx2_AdasHbaSR_On, 3=Cx3_AdasHbaSR_Invalid}
    USM_AdasHDASetReq: category=VALUE, base-type=DataType/uint8, compu {0=Cx0_AdasHDASR_Default, 1=Cx1_AdasHDASR_Function_Off, 2=Cx2_AdasHDASR_Function_On, 3=Cx3_AdasHDASR_Invalid}
    USM_AdasISLAAutoSetReq: category=VALUE, base-type=DataType/uint8, compu {0=Cx0_AdasISLAASR_Default, 1=Cx1_AdasISLAASR_Auto_Off, 2=Cx2_AdasISLAASR_Auto_On, 3=Cx3_AdasISLAASR_Invalid}
    USM_AdasISLASetReq: category=VALUE, base-type=DataType/uint8, compu {0=Cx0_AdasISLASR_Default, 1=Cx1_AdasISLASR_Off, 2=Cx2_AdasISLASR_ISLW, 3=Cx3_AdasISLASR_ISLA, 4=Cx4_AdasISLASR_Reserved, 5=Cx5_AdasISLASR_Reserved, 6=Cx6_AdasISLASR_Reserved, 7=Cx7_AdasISLASR_Invalid}
    USM_AdasISLWSetReq: category=VALUE, base-type=DataType/uint8, compu {0=Cx0_AdasISLWSR_Default, 1=Cx1_AdasISLWSR_Disable, 2=Cx2_AdasISLWSR_Enable, 3=Cx3_AdasISLWSR_Invalid}
    USM_AdasLkaModSetReq: category=VALUE, base-type=DataType/uint8, compu {0=Cx0_AdasLkaMSR_Default, 1=Cx1_AdasLkaMSR_LDW_mode, 2=Cx2_AdasLkaMSR_LKA_mode, 3=Cx3_AdasLkaMSR_ACTIVE_LKA, 4=Cx4_AdasLkaMSR_LDW_ON, 5=Cx5_AdasLkaMSR_LDW_OFF, 6=Cx6_AdasLkaMSR_LDW_LKA_OFF, 7=Cx7_AdasLkaMSR_Invalid}
    USM_AdasLVDASetReq: category=VALUE, base-type=DataType/uint8, compu {0=Cx0_AdasLVDASR_Default, 1=Cx1_AdasLVDASR_Off, 2=Cx2_AdasLVDASR_On, 3=Cx3_AdasLVDASR_Invalid}
    USM_AdasNSCCCamSetReq: category=VALUE, base-type=DataType/uint8, compu {0=Cx0_AdasNSCCCSR_Default, 1=Cx1_AdasNSCCCSR_Disable, 2=Cx2_AdasNSCCCSR_Enable, 3=Cx3_AdasNSCCCSR_Invalid}
    USM_AdasSCCDrvModSetReq: category=VALUE, base-type=DataType/uint8, compu {0=Cx0_AdasSCCDMSR_Default, 1=Cx1_AdasSCCDMSR_Comfort, 2=Cx2_AdasSCCDMSR_Normal, 3=Cx3_AdasSCCDMSR_Dynamic, 4=Cx4_AdasSCCDMSR_Reserved, 5=Cx5_AdasSCCDMSR_Reserved, 6=Cx6_AdasSCCDMSR_Reserved, 7=Cx7_AdasSCCDMSR_Invalid}
    USM_AdasUSMResetReq: category=VALUE, base-type=DataType/uint8, compu {0=Cx0_AdasUSMRR_Default, 1=Cx1_AdasUSMRR_Reset, 2=Cx2_AdasUSMRR_Reserved, 3=Cx3_AdasUSMRR_Invalid}
    USM_AdasWrngTimingSetReq: category=VALUE, base-type=DataType/uint8, compu {0=Cx0_AdasWrngTSR_Default, 1=Cx1_AdasWrngTSR_Late, 2=Cx2_AdasWrngTSR_Normal, 3=Cx3_AdasWrngTSR_Reserved, 4=Cx4_AdasWrngTSR_Reserved, 5=Cx5_AdasWrngTSR_Reserved, 6=Cx6_AdasWrngTSR_Reserved, 7=Cx7_AdasWrngTSR_Invalid (Invliad)}
    USM_Fca1stWrngSetReq: category=VALUE, base-type=DataType/uint8, compu {0=Cx0_USMFca1stWSR_Default, 1=Cx1_USMFca1stWSR_LDW_Mode, 2=Cx2_USMFca1stWSR_LKA_Mode, 3=Cx3_USMFca1stWSR_Reserved, 4=Cx4_USMFca1stWSR_Reserved, 5=Cx5_USMFca1stWSR_Reserved, 6=Cx6_USMFca1stWSR_Reserved, 7=Cx7_USMFca1stWSR_Invalid}
    USM_ISLAOffstSetReq: category=VALUE, base-type=DataType/uint8, compu {0=Cx0_ISLAOSR_Default, 1=Cx1_ISLAOSR_10kph_5mph, 2=Cx2_ISLAOSR_5kph_3mph, 3=Cx3_ISLAOSR_0, 4=Cx4_ISLAOSR_5kph_3mph, 5=Cx5_ISLAOSR_10kph_5mph, 6=Cx6_ISLAOSR_Reserved, 7=Cx7_ISLAOSR_Invalid}
    USM_StaRst1Req: category=VALUE, base-type=DataType/uint8, compu {0=Cx0_StaR1R_Default, 1=Cx1_StaR1R_Reset, 2=Cx2_StaR1R_Not_Used, 3=Cx3_StaR1R_Error_Indicator}
package /PortInterfaces
  11 x sender receiver interface:
    SG_BCM_08_200ms: invalidation-policy{data-element=SG_BCM_08_200ms, handle-invalid=DONT-INVALIDATE}
      data SG_BCM_08_200ms: type=HSYS_BCM_08_200ms_T
    SG_CGW1: invalidation-policy{data-element=SG_CGW1, handle-invalid=DONT-INVALIDATE}
      data SG_CGW1: type=HSYS_CGW1_T
    SG_CLU_01_20ms: invalidation-policy{data-element=SG_CLU_01_20ms, handle-invalid=DONT-INVALIDATE}
      data SG_CLU_01_20ms: type=HSYS_CLU_01_20ms_T
    SG_CLU_04_00ms: invalidation-policy{data-element=SG_CLU_04_00ms, handle-invalid=DONT-INVALIDATE}
      data SG_CLU_04_00ms: type=HSYS_CLU_04_00ms_T
    SG_CLU_05_00ms: invalidation-policy{data-element=SG_CLU_05_00ms, handle-invalid=DONT-INVALIDATE}
      data SG_CLU_05_00ms: type=HSYS_CLU_05_00ms_T
    SG_CLU_12_00ms: invalidation-policy{data-element=SG_CLU_12_00ms, handle-invalid=DONT-INVALIDATE}
      data SG_CLU_12_00ms: type=HSYS_CLU_12_00ms_T
    SG_CLU_13_00ms: invalidation-policy{data-element=SG_CLU_13_00ms, handle-invalid=DONT-INVALIDATE}
      data SG_CLU_13_00ms: type=HSYS_CLU_13_00ms_T
    SG_CLU11_1: invalidation-policy{data-element=SG_CLU11, handle-invalid=DONT-INVALIDATE}
      data SG_CLU11: type=HSYS_CLU11_T
    SG_CLU19: invalidation-policy{data-element=SG_CLU19, handle-invalid=DONT-INVALIDATE}
      data SG_CLU19: type=HSYS_CLU19_T
    SG_MDPS_01_10ms: invalidation-policy{data-element=SG_MDPS_01_10ms, handle-invalid=DONT-INVALIDATE}
      data SG_MDPS_01_10ms: type=HSYS_MDPS_01_10ms_T
    SG_MDPS12_FS: invalidation-policy{data-element=SG_MDPS12_FS, handle-invalid=DONT-INVALIDATE}
      data SG_MDPS12_FS: type=HSYS_MDPS12_T
